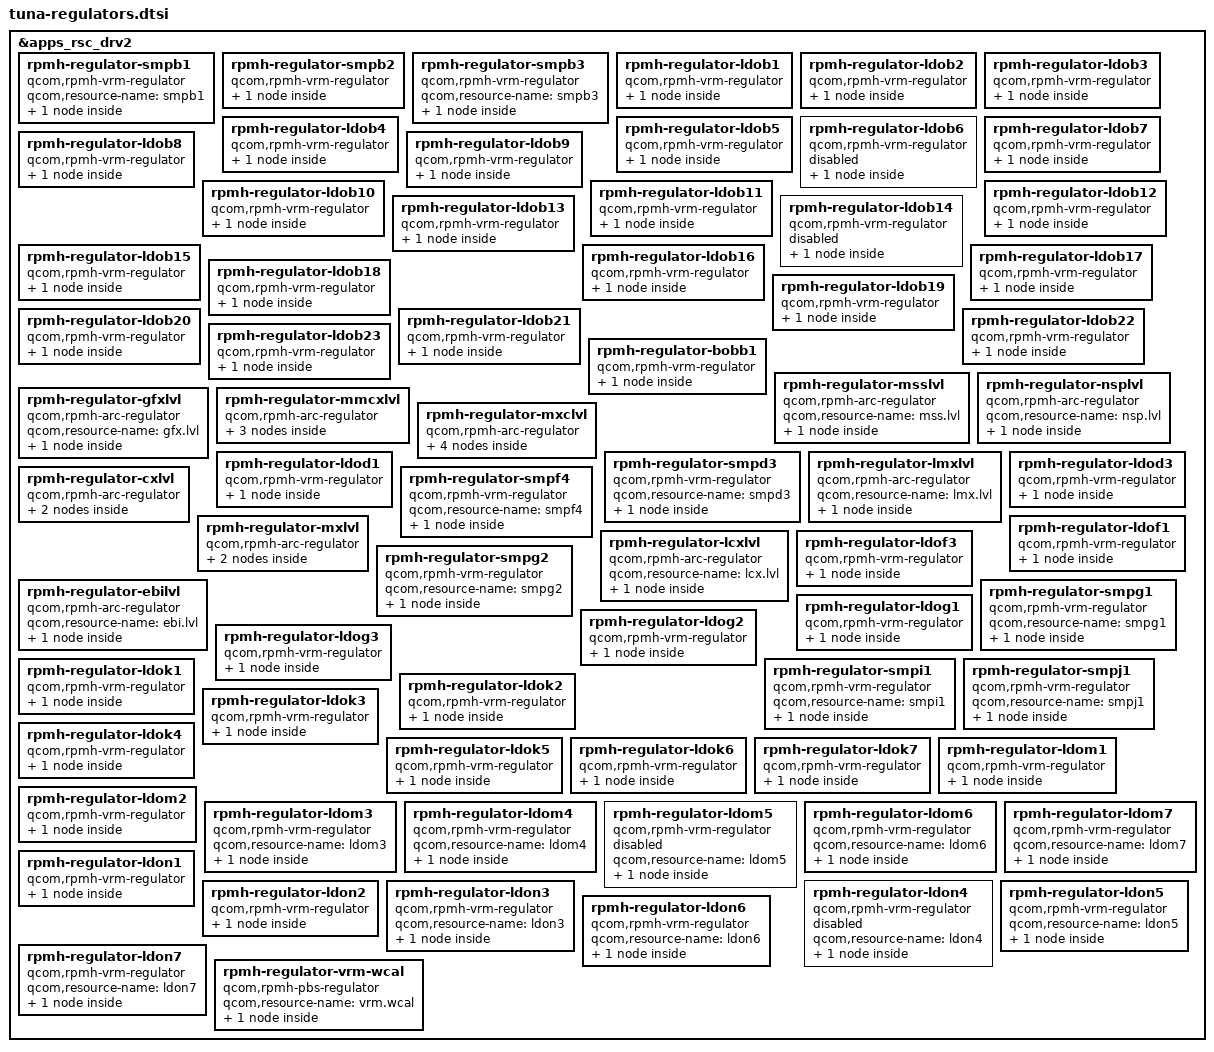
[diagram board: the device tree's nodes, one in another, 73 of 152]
// SPDX-License-Identifier: BSD-3-Clause
/*
 * Copyright (c) Qualcomm Technologies, Inc. and/or its subsidiaries.
 */

#include <dt-bindings/regulator/qcom,rpmh-regulator-levels.h>

&apps_rsc_drv2 {
	rpmh-regulator-smpb1 {
		compatible = "qcom,rpmh-vrm-regulator";
		qcom,resource-name = "smpb1";

		S1B: pmxr2230_s1: vreg-pmxr2230-s1 {
			regulator-name = "pmxr2230_s1";
			qcom,set = <RPMH_REGULATOR_SET_ALL>;
			regulator-min-microvolt = <1840000>;
			regulator-max-microvolt = <2104000>;
			qcom,init-voltage = <1840000>;
		};
	};

	rpmh-regulator-smpb2 {
		compatible = "qcom,rpmh-vrm-regulator";
		qcom,resource-name = "smpb2";
		qcom,regulator-type = "pmic5-ftsmps";
		qcom,supported-modes = <RPMH_REGULATOR_MODE_RET
					RPMH_REGULATOR_MODE_HPM>;
		qcom,mode-threshold-currents = <0 50000>;

		S2B: pmxr2230_s2: vreg-pmxr2230-s2 {
			regulator-name = "pmxr2230_s2";
			qcom,set = <RPMH_REGULATOR_SET_ALL>;
			regulator-min-microvolt = <1240000>;
			regulator-max-microvolt = <1408000>;
			qcom,init-voltage = <1240000>;
			qcom,init-mode = <RPMH_REGULATOR_MODE_RET>;
		};
	};

	rpmh-regulator-smpb3 {
		compatible = "qcom,rpmh-vrm-regulator";
		qcom,resource-name = "smpb3";

		S3B: pmxr2230_s3: vreg-pmxr2230-s3 {
			regulator-name = "pmxr2230_s3";
			qcom,set = <RPMH_REGULATOR_SET_ALL>;
			regulator-min-microvolt = <750000>;
			regulator-max-microvolt = <1040000>;
			qcom,init-voltage = <952000>;
		};
	};

	rpmh-regulator-ldob1 {
		compatible = "qcom,rpmh-vrm-regulator";
		qcom,resource-name = "ldob1";
		qcom,regulator-type = "pmic5-ldo";
		qcom,supported-modes =
			<RPMH_REGULATOR_MODE_LPM
			 RPMH_REGULATOR_MODE_HPM>;
		qcom,mode-threshold-currents = <0 30000>;

		L1B: pmxr2230_l1: vreg-pmxr2230-l1 {
			regulator-name = "pmxr2230_l1";
			qcom,set = <RPMH_REGULATOR_SET_ALL>;
			regulator-min-microvolt = <866000>;
			regulator-max-microvolt = <958000>;
			qcom,init-voltage = <912000>;
			qcom,init-mode = <RPMH_REGULATOR_MODE_HPM>;
		};
	};

	rpmh-regulator-ldob2 {
		compatible = "qcom,rpmh-vrm-regulator";
		qcom,resource-name = "ldob2";
		qcom,regulator-type = "pmic5-ldo";
		qcom,supported-modes =
			<RPMH_REGULATOR_MODE_LPM
			 RPMH_REGULATOR_MODE_HPM>;
		qcom,mode-threshold-currents = <0 30000>;
		proxy-supply = <&L2B>;

		L2B: pmxr2230_l2: vreg-pmxr2230-l2 {
			regulator-name = "pmxr2230_l2";
			qcom,set = <RPMH_REGULATOR_SET_ALL>;
			regulator-min-microvolt = <880000>;
			regulator-max-microvolt = <925000>;
			qcom,init-voltage = <880000>;
			qcom,init-mode = <RPMH_REGULATOR_MODE_HPM>;
			qcom,proxy-consumer-enable;
			qcom,proxy-consumer-current = <98000>;
		};
	};

	rpmh-regulator-ldob3 {
		compatible = "qcom,rpmh-vrm-regulator";
		qcom,resource-name = "ldob3";
		qcom,regulator-type = "pmic5-ldo";
		qcom,supported-modes =
			<RPMH_REGULATOR_MODE_LPM
			 RPMH_REGULATOR_MODE_HPM>;
		qcom,mode-threshold-currents = <0 30000>;

		L3B: pmxr2230_l3: vreg-pmxr2230-l3 {
			regulator-name = "pmxr2230_l3";
			qcom,set = <RPMH_REGULATOR_SET_ALL>;
			regulator-min-microvolt = <720000>;
			regulator-max-microvolt = <950000>;
			qcom,init-voltage = <880000>;
			qcom,init-mode = <RPMH_REGULATOR_MODE_HPM>;
		};
	};

	rpmh-regulator-ldob4 {
		compatible = "qcom,rpmh-vrm-regulator";
		qcom,resource-name = "ldob4";
		qcom,regulator-type = "pmic5-ldo";
		qcom,supported-modes =
			<RPMH_REGULATOR_MODE_LPM
			 RPMH_REGULATOR_MODE_HPM>;
		qcom,mode-threshold-currents = <0 30000>;
		proxy-supply = <&L4B>;

		L4B: pmxr2230_l4: vreg-pmxr2230-l4 {
			regulator-name = "pmxr2230_l4";
			qcom,set = <RPMH_REGULATOR_SET_ALL>;
			regulator-min-microvolt = <1200000>;
			regulator-max-microvolt = <1200000>;
			qcom,init-voltage = <1200000>;
			qcom,init-mode = <RPMH_REGULATOR_MODE_HPM>;
			qcom,proxy-consumer-enable;
			qcom,proxy-consumer-current = <16600>;
		};
	};

	rpmh-regulator-ldob5 {
		compatible = "qcom,rpmh-vrm-regulator";
		qcom,resource-name = "ldob5";
		qcom,regulator-type = "pmic5-ldo";
		qcom,supported-modes =
			<RPMH_REGULATOR_MODE_RET
			 RPMH_REGULATOR_MODE_LPM
			 RPMH_REGULATOR_MODE_HPM>;
		qcom,mode-threshold-currents = <0 10000 30000>;

		L5B: pmxr2230_l5: vreg-pmxr2230-l5 {
			regulator-name = "pmxr2230_l5";
			qcom,set = <RPMH_REGULATOR_SET_ALL>;
			regulator-min-microvolt = <1200000>;
			regulator-max-microvolt = <1200000>;
			qcom,init-voltage = <1200000>;
			qcom,init-mode = <RPMH_REGULATOR_MODE_LPM>;
		};
	};

	rpmh-regulator-ldob6 {
		compatible = "qcom,rpmh-vrm-regulator";
		qcom,resource-name = "ldob6";
		qcom,regulator-type = "pmic5-ldo";
		qcom,supported-modes =
			<RPMH_REGULATOR_MODE_LPM
			 RPMH_REGULATOR_MODE_HPM>;
		qcom,mode-threshold-currents = <0 30000>;
		status = "disabled";

		L6B: pmxr2230_l6: vreg-pmxr2230-l6 {
			regulator-name = "pmxr2230_l6";
			qcom,set = <RPMH_REGULATOR_SET_ALL>;
			regulator-min-microvolt = <1170000>;
			regulator-max-microvolt = <1370000>;
			qcom,init-voltage = <1256000>;
			qcom,init-mode = <RPMH_REGULATOR_MODE_HPM>;
			status = "disabled";
		};
	};

	rpmh-regulator-ldob7 {
		compatible = "qcom,rpmh-vrm-regulator";
		qcom,resource-name = "ldob7";
		qcom,regulator-type = "pmic5-ldo";
		qcom,supported-modes =
			<RPMH_REGULATOR_MODE_LPM
			 RPMH_REGULATOR_MODE_HPM>;
		qcom,mode-threshold-currents = <0 30000>;

		L7B: pmxr2230_l7: vreg-pmxr2230-l7 {
			regulator-name = "pmxr2230_l7";
			qcom,set = <RPMH_REGULATOR_SET_ALL>;
			regulator-min-microvolt = <1800000>;
			regulator-max-microvolt = <1800000>;
			qcom,init-voltage = <1800000>;
			qcom,init-mode = <RPMH_REGULATOR_MODE_HPM>;
		};
	};

	rpmh-regulator-ldob8 {
		compatible = "qcom,rpmh-vrm-regulator";
		qcom,resource-name = "ldob8";
		qcom,regulator-type = "pmic5-ldo";
		qcom,supported-modes =
			<RPMH_REGULATOR_MODE_LPM
			 RPMH_REGULATOR_MODE_HPM>;
		qcom,mode-threshold-currents = <0 30000>;
		proxy-supply = <&L8B>;

		L8B: pmxr2230_l8: vreg-pmxr2230-l8 {
			regulator-name = "pmxr2230_l8";
			qcom,set = <RPMH_REGULATOR_SET_ALL>;
			regulator-min-microvolt = <1800000>;
			regulator-max-microvolt = <1800000>;
			qcom,init-voltage = <1800000>;
			qcom,init-mode = <RPMH_REGULATOR_MODE_HPM>;
			qcom,proxy-consumer-enable;
			qcom,proxy-consumer-current = <154000>;
		};
	};

	rpmh-regulator-ldob9 {
		compatible = "qcom,rpmh-vrm-regulator";
		qcom,resource-name = "ldob9";
		qcom,regulator-type = "pmic5-ldo";
		qcom,supported-modes =
			<RPMH_REGULATOR_MODE_LPM
			 RPMH_REGULATOR_MODE_HPM>;
		qcom,mode-threshold-currents = <0 30000>;

		L9B: pmxr2230_l9: vreg-pmxr2230-l9 {
			regulator-name = "pmxr2230_l9";
			qcom,set = <RPMH_REGULATOR_SET_ALL>;
			regulator-min-microvolt = <756000>;
			regulator-max-microvolt = <816000>;
			qcom,init-voltage = <800000>;
			qcom,init-mode = <RPMH_REGULATOR_MODE_HPM>;
		};
	};

	rpmh-regulator-ldob10 {
		compatible = "qcom,rpmh-vrm-regulator";
		qcom,resource-name = "ldob10";
		qcom,regulator-type = "pmic5-ldo";
		qcom,supported-modes =
			<RPMH_REGULATOR_MODE_LPM
			 RPMH_REGULATOR_MODE_HPM>;
		qcom,mode-threshold-currents = <0 30000>;

		L10B: pmxr2230_l10: vreg-pmxr2230-l10 {
			regulator-name = "pmxr2230_l10";
			qcom,set = <RPMH_REGULATOR_SET_ALL>;
			regulator-min-microvolt = <866000>;
			regulator-max-microvolt = <931000>;
			qcom,init-voltage = <912000>;
			qcom,init-mode = <RPMH_REGULATOR_MODE_HPM>;
		};
	};

	rpmh-regulator-ldob11 {
		compatible = "qcom,rpmh-vrm-regulator";
		qcom,resource-name = "ldob11";
		qcom,regulator-type = "pmic5-ldo";
		qcom,supported-modes =
			<RPMH_REGULATOR_MODE_LPM
			 RPMH_REGULATOR_MODE_HPM>;
		qcom,mode-threshold-currents = <0 30000>;

		L11B: pmxr2230_l11: vreg-pmxr2230-l11 {
			regulator-name = "pmxr2230_l11";
			qcom,set = <RPMH_REGULATOR_SET_ALL>;
			regulator-min-microvolt = <1080000>;
			regulator-max-microvolt = <2000000>;
			qcom,init-voltage = <1800000>;
			qcom,init-mode = <RPMH_REGULATOR_MODE_HPM>;
		};
	};

	rpmh-regulator-ldob12 {
		compatible = "qcom,rpmh-vrm-regulator";
		qcom,resource-name = "ldob12";
		qcom,regulator-type = "pmic5-ldo";
		qcom,supported-modes =
			<RPMH_REGULATOR_MODE_LPM
			 RPMH_REGULATOR_MODE_HPM>;
		qcom,mode-threshold-currents = <0 10000>;

		L12B: pmxr2230_l12: vreg-pmxr2230-l12 {
			regulator-name = "pmxr2230_l12";
			qcom,set = <RPMH_REGULATOR_SET_ALL>;
			regulator-min-microvolt = <2400000>;
			regulator-max-microvolt = <3300000>;
			qcom,init-voltage = <2504000>;
			qcom,init-mode = <RPMH_REGULATOR_MODE_HPM>;
		};
	};

	rpmh-regulator-ldob13 {
		compatible = "qcom,rpmh-vrm-regulator";
		qcom,resource-name = "ldob13";
		qcom,regulator-type = "pmic5-ldo";
		qcom,supported-modes =
			<RPMH_REGULATOR_MODE_LPM
			 RPMH_REGULATOR_MODE_HPM>;
		qcom,mode-threshold-currents = <0 10000>;

		L13B: pmxr2230_l13: vreg-pmxr2230-l13 {
			regulator-name = "pmxr2230_l13";
			qcom,set = <RPMH_REGULATOR_SET_ALL>;
			regulator-min-microvolt = <2700000>;
			regulator-max-microvolt = <3300000>;
			qcom,init-voltage = <2960000>;
			qcom,init-mode = <RPMH_REGULATOR_MODE_HPM>;
		};
	};

	rpmh-regulator-ldob14 {
		compatible = "qcom,rpmh-vrm-regulator";
		qcom,resource-name = "ldob14";
		qcom,regulator-type = "pmic5-ldo";
		qcom,supported-modes =
			<RPMH_REGULATOR_MODE_LPM
			 RPMH_REGULATOR_MODE_HPM>;
		qcom,mode-threshold-currents = <0 10000>;
		status = "disabled";

		L14B: pmxr2230_l14: vreg-pmxr2230-l14 {
			regulator-name = "pmxr2230_l14";
			qcom,set = <RPMH_REGULATOR_SET_ALL>;
			regulator-min-microvolt = <1504000>;
			regulator-max-microvolt = <3544000>;
			qcom,init-voltage = <2800000>;
			qcom,init-mode = <RPMH_REGULATOR_MODE_HPM>;
			status = "disabled";
		};
	};

	rpmh-regulator-ldob15 {
		compatible = "qcom,rpmh-vrm-regulator";
		qcom,resource-name = "ldob15";
		qcom,regulator-type = "pmic5-ldo";
		qcom,supported-modes =
			<RPMH_REGULATOR_MODE_LPM
			 RPMH_REGULATOR_MODE_HPM>;
		qcom,mode-threshold-currents = <0 10000>;

		L15B: pmxr2230_l15: vreg-pmxr2230-l15 {
			regulator-name = "pmxr2230_l15";
			qcom,set = <RPMH_REGULATOR_SET_ALL>;
			regulator-min-microvolt = <1620000>;
			regulator-max-microvolt = <3300000>;
			qcom,init-voltage = <1800000>;
			qcom,init-mode = <RPMH_REGULATOR_MODE_HPM>;
		};
	};

	rpmh-regulator-ldob16 {
		compatible = "qcom,rpmh-vrm-regulator";
		qcom,resource-name = "ldob16";
		qcom,regulator-type = "pmic5-ldo";
		qcom,supported-modes =
			<RPMH_REGULATOR_MODE_LPM
			 RPMH_REGULATOR_MODE_HPM>;
		qcom,mode-threshold-currents = <0 10000>;

		L16B: pmxr2230_l16: vreg-pmxr2230-l16 {
			regulator-name = "pmxr2230_l16";
			qcom,set = <RPMH_REGULATOR_SET_ALL>;
			regulator-min-microvolt = <2600000>;
			regulator-max-microvolt = <3544000>;
			qcom,init-voltage = <3008000>;
			qcom,init-mode = <RPMH_REGULATOR_MODE_HPM>;
		};
	};

	rpmh-regulator-ldob17 {
		compatible = "qcom,rpmh-vrm-regulator";
		qcom,resource-name = "ldob17";
		qcom,regulator-type = "pmic5-ldo";
		qcom,supported-modes =
			<RPMH_REGULATOR_MODE_LPM
			 RPMH_REGULATOR_MODE_HPM>;
		qcom,mode-threshold-currents = <0 10000>;

		L17B: pmxr2230_l17: vreg-pmxr2230-l17 {
			regulator-name = "pmxr2230_l17";
			qcom,set = <RPMH_REGULATOR_SET_ALL>;
			regulator-min-microvolt = <2700000>;
			regulator-max-microvolt = <3544000>;
			qcom,init-voltage = <3104000>;
			qcom,init-mode = <RPMH_REGULATOR_MODE_HPM>;
		};
	};

	rpmh-regulator-ldob18 {
		compatible = "qcom,rpmh-vrm-regulator";
		qcom,resource-name = "ldob18";
		qcom,regulator-type = "pmic5-ldo";
		qcom,supported-modes =
			<RPMH_REGULATOR_MODE_LPM
			 RPMH_REGULATOR_MODE_HPM>;
		qcom,mode-threshold-currents = <0 10000>;

		L18B: pmxr2230_l18: vreg-pmxr2230-l18 {
			regulator-name = "pmxr2230_l18";
			qcom,set = <RPMH_REGULATOR_SET_ALL>;
			regulator-min-microvolt = <1600000>;
			regulator-max-microvolt = <3544000>;
			qcom,init-voltage = <2800000>;
			qcom,init-mode = <RPMH_REGULATOR_MODE_HPM>;
		};
	};

	rpmh-regulator-ldob19 {
		compatible = "qcom,rpmh-vrm-regulator";
		qcom,resource-name = "ldob19";
		qcom,regulator-type = "pmic5-ldo";
		qcom,supported-modes =
			<RPMH_REGULATOR_MODE_LPM
			 RPMH_REGULATOR_MODE_HPM>;
		qcom,mode-threshold-currents = <0 10000>;
		proxy-supply = <&L19B>;

		L19B: pmxr2230_l19: vreg-pmxr2230-l19 {
			regulator-name = "pmxr2230_l19";
			qcom,set = <RPMH_REGULATOR_SET_ALL>;
			regulator-min-microvolt = <2650000>;
			regulator-max-microvolt = <3544000>;
			qcom,init-voltage = <3000000>;
			qcom,init-mode = <RPMH_REGULATOR_MODE_HPM>;
			qcom,proxy-consumer-enable;
			qcom,proxy-consumer-current = <10000>;
		};
	};

	rpmh-regulator-ldob20 {
		compatible = "qcom,rpmh-vrm-regulator";
		qcom,resource-name = "ldob20";
		qcom,regulator-type = "pmic5-ldo";
		qcom,supported-modes =
			<RPMH_REGULATOR_MODE_LPM
			 RPMH_REGULATOR_MODE_HPM>;
		qcom,mode-threshold-currents = <0 10000>;

		L20B: pmxr2230_l20: vreg-pmxr2230-l20 {
			regulator-name = "pmxr2230_l20";
			qcom,set = <RPMH_REGULATOR_SET_ALL>;
			regulator-min-microvolt = <1504000>;
			regulator-max-microvolt = <3544000>;
			qcom,init-voltage = <1800000>;
			qcom,init-mode = <RPMH_REGULATOR_MODE_HPM>;
		};
	};

	rpmh-regulator-ldob21 {
		compatible = "qcom,rpmh-vrm-regulator";
		qcom,resource-name = "ldob21";
		qcom,regulator-type = "pmic5-ldo";
		qcom,supported-modes =
			<RPMH_REGULATOR_MODE_LPM
			 RPMH_REGULATOR_MODE_HPM>;
		qcom,mode-threshold-currents = <0 10000>;

		L21B: pmxr2230_l21: vreg-pmxr2230-l21 {
			regulator-name = "pmxr2230_l21";
			qcom,set = <RPMH_REGULATOR_SET_ALL>;
			regulator-min-microvolt = <1504000>;
			regulator-max-microvolt = <3544000>;
			qcom,init-voltage = <1800000>;
			qcom,init-mode = <RPMH_REGULATOR_MODE_HPM>;
		};
	};

	rpmh-regulator-ldob22 {
		compatible = "qcom,rpmh-vrm-regulator";
		qcom,resource-name = "ldob22";
		qcom,regulator-type = "pmic5-ldo";
		qcom,supported-modes =
			<RPMH_REGULATOR_MODE_LPM
			 RPMH_REGULATOR_MODE_HPM>;
		qcom,mode-threshold-currents = <0 10000>;

		L22B: pmxr2230_l22: vreg-pmxr2230-l22 {
			regulator-name = "pmxr2230_l22";
			qcom,set = <RPMH_REGULATOR_SET_ALL>;
			regulator-min-microvolt = <2700000>;
			regulator-max-microvolt = <3544000>;
			qcom,init-voltage = <3200000>;
			qcom,init-mode = <RPMH_REGULATOR_MODE_HPM>;
		};
	};

	rpmh-regulator-ldob23 {
		compatible = "qcom,rpmh-vrm-regulator";
		qcom,resource-name = "ldob23";
		qcom,regulator-type = "pmic5-ldo";
		qcom,supported-modes =
			<RPMH_REGULATOR_MODE_LPM
			 RPMH_REGULATOR_MODE_HPM>;
		qcom,mode-threshold-currents = <0 10000>;

		L23B: pmxr2230_l23: vreg-pmxr2230-l23 {
			regulator-name = "pmxr2230_l23";
			qcom,set = <RPMH_REGULATOR_SET_ALL>;
			regulator-min-microvolt = <1650000>;
			regulator-max-microvolt = <3544000>;
			qcom,init-voltage = <1800000>;
			qcom,init-mode = <RPMH_REGULATOR_MODE_HPM>;
		};
	};

	rpmh-regulator-bobb1 {
		compatible = "qcom,rpmh-vrm-regulator";
		qcom,resource-name = "bobb1";
		qcom,regulator-type = "pmic5-bob";
		qcom,supported-modes =
			<RPMH_REGULATOR_MODE_PASS
			 RPMH_REGULATOR_MODE_LPM
			 RPMH_REGULATOR_MODE_HPM>;
		qcom,mode-threshold-currents = <0 1000000 2000000>;

		BOB: pmxr2230_bob: vreg-pmxr2230-bob1 {
			regulator-name = "pmxr2230_bob";
			qcom,set = <RPMH_REGULATOR_SET_ALL>;
			regulator-min-microvolt = <3008000>;
			regulator-max-microvolt = <3960000>;
			qcom,init-voltage = <3296000>;
		};
	};

	rpmh-regulator-msslvl {
		compatible = "qcom,rpmh-arc-regulator";
		qcom,resource-name = "mss.lvl";

		VDD_MODEM_LEVEL:
		S1D_LEVEL:
		pm_v6d_s1_level: vreg-pm_v6d-s1-level {
			regulator-name = "pm_v6d_s1_level";
			qcom,set = <RPMH_REGULATOR_SET_ALL>;
			regulator-min-microvolt =
				<RPMH_REGULATOR_LEVEL_RETENTION>;
			regulator-max-microvolt = <RPMH_REGULATOR_LEVEL_MAX>;
			qcom,init-voltage-level =
				<RPMH_REGULATOR_LEVEL_RETENTION>;
		};
	};

	rpmh-regulator-nsplvl {
		compatible = "qcom,rpmh-arc-regulator";
		qcom,resource-name = "nsp.lvl";

		VDD_NSP1_LEVEL:
		S4D_LEVEL:
		pm_v6d_s4_level: vreg-pm_v6d-s4-level {
			regulator-name = "pm-v6d_s4_level";
			qcom,set = <RPMH_REGULATOR_SET_ALL>;
			regulator-min-microvolt =
				<RPMH_REGULATOR_LEVEL_RETENTION>;
			regulator-max-microvolt = <RPMH_REGULATOR_LEVEL_MAX>;
			qcom,init-voltage-level =
				<RPMH_REGULATOR_LEVEL_RETENTION>;
		};
	};

	rpmh-regulator-gfxlvl {
		compatible = "qcom,rpmh-arc-regulator";
		qcom,resource-name = "gfx.lvl";

		VDD_GFX_LEVEL:
		S5F_LEVEL:
		pm_v8f_s5_level: vreg-pm_v8f-s5-level {
			regulator-name = "pm_v8f_s5_level";
			qcom,set = <RPMH_REGULATOR_SET_ALL>;
			regulator-min-microvolt =
				<RPMH_REGULATOR_LEVEL_RETENTION>;
			regulator-max-microvolt = <RPMH_REGULATOR_LEVEL_MAX>;
			qcom,init-voltage-level =
				<RPMH_REGULATOR_LEVEL_RETENTION>;
		};
	};

	rpmh-regulator-mmcxlvl {
		compatible = "qcom,rpmh-arc-regulator";
		qcom,resource-name = "mmcx.lvl";
		proxy-supply = <&VDD_MMCX_LEVEL>;

		VDD_MMCX_LEVEL: VDD_MM_LEVEL: S2F_LEVEL:
		pm_v8f_s2_level: vreg-pm-v8f-s2-level {
			regulator-name = "pm_v8f_s2_level";
			qcom,set = <RPMH_REGULATOR_SET_ALL>;
			regulator-min-microvolt =
				<RPMH_REGULATOR_LEVEL_LOW_SVS_D1>;
			regulator-max-microvolt =
				<RPMH_REGULATOR_LEVEL_MAX>;
			qcom,init-voltage-level =
				<RPMH_REGULATOR_LEVEL_TURBO>;
			qcom,proxy-consumer-enable;
			qcom,proxy-consumer-voltage =
				<RPMH_REGULATOR_LEVEL_TURBO
				 RPMH_REGULATOR_LEVEL_MAX>;
		};

		VDD_MMCX_LEVEL_AO: VDD_MM_LEVEL_AO: S2F_LEVEL_AO:
		pm_v8f_s2_level_ao: vreg-pm-v8f-s2-level-ao {
			regulator-name = "pm_v8f_s2_level_ao";
			qcom,set = <RPMH_REGULATOR_SET_ACTIVE>;
			regulator-min-microvolt =
				<RPMH_REGULATOR_LEVEL_LOW_SVS_D1>;
			regulator-max-microvolt =
				<RPMH_REGULATOR_LEVEL_MAX>;
			qcom,init-voltage-level =
				<RPMH_REGULATOR_LEVEL_LOW_SVS_D1>;
		};

		vreg-pm-v8f-s2-level-so {
			regulator-name = "pm_v8i_s2_level_so";
			qcom,set = <RPMH_REGULATOR_SET_SLEEP>;
			regulator-min-microvolt =
				<RPMH_REGULATOR_LEVEL_LOW_SVS_D1>;
			regulator-max-microvolt =
				<RPMH_REGULATOR_LEVEL_MAX>;
			qcom,init-voltage-level =
				<RPMH_REGULATOR_LEVEL_LOW_SVS_D1>;
		};
	};

	rpmh-regulator-mxclvl {
		compatible = "qcom,rpmh-arc-regulator";
		qcom,resource-name = "mxc.lvl";
		proxy-supply = <&VDD_MXC_LEVEL>;

		VDD_MXC_LEVEL:
		S2D_LEVEL:
		pm_v6d_s2_level: vreg-pm_v6d-s2-level {
			regulator-name = "pm_v6d_s2_level";
			qcom,set = <RPMH_REGULATOR_SET_ALL>;
			regulator-min-microvolt =
				<RPMH_REGULATOR_LEVEL_RETENTION>;
			regulator-max-microvolt = <RPMH_REGULATOR_LEVEL_MAX>;
			qcom,init-voltage-level =
				<RPMH_REGULATOR_LEVEL_TURBO>;
			qcom,proxy-consumer-enable;
			qcom,proxy-consumer-voltage =
				<RPMH_REGULATOR_LEVEL_TURBO
					RPMH_REGULATOR_LEVEL_MAX>;
		};

		VDD_MXC_LEVEL_AO:
		S2D_LEVEL_AO:
		pm_v6d_s2_level_ao: vreg-pm_v6d-s2-level-ao {
			regulator-name = "pm_v6d_s2_level_ao";
			qcom,set = <RPMH_REGULATOR_SET_ACTIVE>;
			regulator-min-microvolt =
				<RPMH_REGULATOR_LEVEL_RETENTION>;
			regulator-max-microvolt = <RPMH_REGULATOR_LEVEL_MAX>;
			qcom,init-voltage-level =
				<RPMH_REGULATOR_LEVEL_RETENTION>;
		};

		VDD_MXC_MMCX_VOTER_LEVEL: VDD_MXC_MM_VOTER_LEVEL:
		VDD_MM_MXC_VOTER_LEVEL: vreg-pm_v6d-s2-mmcx-voter-level {
			regulator-name = "pm_v6d_s2_mmcx_voter_level";
			pm_v6d_s2_mmcx_voter_level-parent-supply =
				<&VDD_MMCX_LEVEL>;
			qcom,set = <RPMH_REGULATOR_SET_ALL>;
			regulator-min-microvolt =
				<RPMH_REGULATOR_LEVEL_MIN_SVS>;
			regulator-max-microvolt =
				<RPMH_REGULATOR_LEVEL_MAX>;
			qcom,init-voltage-level =
				<RPMH_REGULATOR_LEVEL_MIN_SVS>;
		};

		VDD_MXC_GFX_VOTER_LEVEL: VDD_GFX_MXC_VOTER_LEVEL:
			vreg-pm_v6d-s2-gfx-voter-level {
			regulator-name = "pm_v6d_s2_gfx_voter_level";
			pm_v6d_s2_gfx_voter_level-parent-supply = <&VDD_GFX_LEVEL>;
			qcom,set = <RPMH_REGULATOR_SET_ALL>;
			regulator-min-microvolt =
				<RPMH_REGULATOR_LEVEL_MIN_SVS>;
			regulator-max-microvolt =
				<RPMH_REGULATOR_LEVEL_MAX>;
			qcom,init-voltage-level =
				<RPMH_REGULATOR_LEVEL_MIN_SVS>;
		};
	};

	rpmh-regulator-smpd3 {
		compatible = "qcom,rpmh-vrm-regulator";
		qcom,resource-name = "smpd3";

		S3D: pm_v6d_s3: vreg-pm_v6d-s3 {
			regulator-name = "pm_v6d_s3";
			qcom,set = <RPMH_REGULATOR_SET_ALL>;
			regulator-min-microvolt = <870000>;
			regulator-max-microvolt = <970000>;
			qcom,init-voltage = <904000>;
		};
	};

	rpmh-regulator-ldod1 {
		compatible = "qcom,rpmh-vrm-regulator";
		qcom,resource-name = "ldod1";
		qcom,regulator-type = "pmic5-ldo";
		qcom,supported-modes =
			<RPMH_REGULATOR_MODE_LPM
			 RPMH_REGULATOR_MODE_HPM>;
		qcom,mode-threshold-currents = <0 30000>;

		L1D: pm_v6d_l1: vreg-pm_v6d-l1 {
			regulator-name = "pm_v6d_l1";
			qcom,set = <RPMH_REGULATOR_SET_ALL>;
			regulator-min-microvolt = <1710000>;
			regulator-max-microvolt = <1950000>;
			qcom,init-voltage = <1800000>;
			qcom,init-mode = <RPMH_REGULATOR_MODE_HPM>;
		};
	};

	rpmh-regulator-lmxlvl {
		compatible = "qcom,rpmh-arc-regulator";
		qcom,resource-name = "lmx.lvl";

		VDD_LPI_MX_LEVEL:
		L2D_LEVEL:
		pm_v6d_l2_level: vreg-pm_v6d-l2-level {
			regulator-name = "pm_v6d_l2_level";
			qcom,set = <RPMH_REGULATOR_SET_ALL>;
			regulator-min-microvolt =
				<RPMH_REGULATOR_LEVEL_RETENTION>;
			regulator-max-microvolt = <RPMH_REGULATOR_LEVEL_MAX>;
			qcom,init-voltage-level =
				<RPMH_REGULATOR_LEVEL_RETENTION>;
		};
	};

	rpmh-regulator-ldod3 {
		compatible = "qcom,rpmh-vrm-regulator";
		qcom,resource-name = "ldod3";
		qcom,regulator-type = "pmic5-ldo";
		qcom,supported-modes =
			<RPMH_REGULATOR_MODE_LPM
			 RPMH_REGULATOR_MODE_HPM>;
		qcom,mode-threshold-currents = <0 30000>;
		proxy-supply = <&L3D>;

		L3D: pm_v6d_l3: vreg-pm_v6d-l3 {
			regulator-name = "pm_v6d_l3";
			qcom,set = <RPMH_REGULATOR_SET_ALL>;
			regulator-min-microvolt = <1030000>;
			regulator-max-microvolt = <1100000>;
			qcom,init-voltage = <1060000>;
			qcom,init-mode = <RPMH_REGULATOR_MODE_HPM>;
			qcom,proxy-consumer-enable;
			qcom,proxy-consumer-current = <220000>;
		};
	};

	rpmh-regulator-cxlvl {
		compatible = "qcom,rpmh-arc-regulator";
		qcom,resource-name = "cx.lvl";
		proxy-supply = <&VDD_CX_LEVEL>;

		VDD_CX_LEVEL:
		S1F_LEVEL:
		pm_v8f_s1_level: vreg-pm_v8f-s1-level {
			regulator-name = "pm_v8f_s1_level";
			qcom,set = <RPMH_REGULATOR_SET_ALL>;
			regulator-min-microvolt =
				<RPMH_REGULATOR_LEVEL_RETENTION>;
			regulator-max-microvolt = <RPMH_REGULATOR_LEVEL_MAX>;
			qcom,init-voltage-level =
				<RPMH_REGULATOR_LEVEL_TURBO>;
			qcom,proxy-consumer-enable;
			qcom,proxy-consumer-voltage =
				<RPMH_REGULATOR_LEVEL_TURBO
				RPMH_REGULATOR_LEVEL_MAX>;
		};

		VDD_CX_LEVEL_AO:
		S1F_LEVEL_AO:
		pm_v8f_s1_level_ao: vreg-pm_v8f-s1-level-ao {
			regulator-name = "pm_v8f_s1_level_ao";
			qcom,set = <RPMH_REGULATOR_SET_ACTIVE>;
			regulator-min-microvolt =
				<RPMH_REGULATOR_LEVEL_RETENTION>;
			regulator-max-microvolt = <RPMH_REGULATOR_LEVEL_MAX>;
			qcom,init-voltage-level =
				<RPMH_REGULATOR_LEVEL_RETENTION>;
		};
	};

	rpmh-regulator-smpf4 {
		compatible = "qcom,rpmh-vrm-regulator";
		qcom,resource-name = "smpf4";

		S4F: pm_v8f_s4: vreg-pm_v8f-s4 {
			regulator-name = "pm_v8f_s4";
			qcom,set = <RPMH_REGULATOR_SET_ALL>;
			regulator-min-microvolt = <300000>;
			regulator-max-microvolt = <570000>;
			qcom,init-voltage = <500000>;
		};
	};

	rpmh-regulator-mxlvl {
		compatible = "qcom,rpmh-arc-regulator";
		qcom,resource-name = "mx.lvl";
		proxy-supply = <&VDD_MXA_LEVEL>;

		VDD_MX_LEVEL:
		VDD_MXA_LEVEL:
		S8F_LEVEL:
		pm_v8f_s8_level: vreg-pm_v8f-s8-level {
			regulator-name = "pm_v8f_s8_level";
			qcom,set = <RPMH_REGULATOR_SET_ALL>;
			regulator-min-microvolt =
				<RPMH_REGULATOR_LEVEL_RETENTION>;
			regulator-max-microvolt = <RPMH_REGULATOR_LEVEL_MAX>;
			qcom,init-voltage-level =
				<RPMH_REGULATOR_LEVEL_TURBO>;
			qcom,proxy-consumer-enable;
			qcom,proxy-consumer-voltage =
				<RPMH_REGULATOR_LEVEL_TURBO
				RPMH_REGULATOR_LEVEL_MAX>;
		};

		VDD_MXA_LEVEL_AO:
		S8F_LEVEL_AO:
		pm_v8f_s8_level_ao: vreg-pm_v8f-s8-level-ao {
			regulator-name = "pm_v8f_s8_level_ao";
			qcom,set = <RPMH_REGULATOR_SET_ACTIVE>;
			regulator-min-microvolt =
				<RPMH_REGULATOR_LEVEL_RETENTION>;
			regulator-max-microvolt = <RPMH_REGULATOR_LEVEL_MAX>;
			qcom,init-voltage-level =
				<RPMH_REGULATOR_LEVEL_RETENTION>;
		};
	};

	rpmh-regulator-ldof1 {
		compatible = "qcom,rpmh-vrm-regulator";
		qcom,resource-name = "ldof1";
		qcom,regulator-type = "pmic5-ldo";
		qcom,supported-modes =
			<RPMH_REGULATOR_MODE_LPM
			 RPMH_REGULATOR_MODE_HPM>;
		qcom,mode-threshold-currents = <0 30000>;

		L1F: pm_v8f_l1: vreg-pm_v8f-l1 {
			regulator-name = "pm_v8f_l1";
			qcom,set = <RPMH_REGULATOR_SET_ALL>;
			regulator-min-microvolt = <866000>;
			regulator-max-microvolt = <958000>;
			qcom,init-voltage = <912000>;
			qcom,init-mode = <RPMH_REGULATOR_MODE_HPM>;
		};
	};

	rpmh-regulator-lcxlvl {
		compatible = "qcom,rpmh-arc-regulator";
		qcom,resource-name = "lcx.lvl";

		VDD_LPI_CX_LEVEL:
		L2F_LEVEL:
		pm_v8f_l2_level: vreg-pm_v8-l2-level {
			regulator-name = "pm_v8f_l2_level";
			qcom,set = <RPMH_REGULATOR_SET_ALL>;
			regulator-min-microvolt =
				<RPMH_REGULATOR_LEVEL_RETENTION>;
			regulator-max-microvolt = <RPMH_REGULATOR_LEVEL_MAX>;
			qcom,init-voltage-level =
				<RPMH_REGULATOR_LEVEL_RETENTION>;
		};
	};

	rpmh-regulator-ldof3 {
		compatible = "qcom,rpmh-vrm-regulator";
		qcom,resource-name = "ldof3";
		qcom,regulator-type = "pmic5-ldo";
		qcom,supported-modes =
			<RPMH_REGULATOR_MODE_LPM
			 RPMH_REGULATOR_MODE_HPM>;
		qcom,mode-threshold-currents = <0 30000>;
		proxy-supply = <&L3F>;

		L3F: pm_v8f_l3: vreg-pm_v8f-l3 {
			regulator-name = "pm_v8f_l3";
			qcom,set = <RPMH_REGULATOR_SET_ALL>;
			regulator-min-microvolt = <1200000>;
			regulator-max-microvolt = <1200000>;
			qcom,proxy-consumer-enable;
			qcom,proxy-consumer-current = <31000>;
			qcom,init-voltage = <1200000>;
			qcom,init-mode = <RPMH_REGULATOR_MODE_HPM>;
		};
	};

	rpmh-regulator-smpg2 {
		compatible = "qcom,rpmh-vrm-regulator";
		qcom,resource-name = "smpg2";

		S2G: pm_v6g_s2: vreg-pm_v6g-s2 {
			regulator-name = "pm_v6g_s2";
			qcom,set = <RPMH_REGULATOR_SET_ALL>;
			regulator-min-microvolt = <1010000>;
			regulator-max-microvolt = <1170000>;
			qcom,init-voltage = <1080000>;
		};
	};

	rpmh-regulator-ebilvl {
		compatible = "qcom,rpmh-arc-regulator";
		qcom,resource-name = "ebi.lvl";

		VDD_EBI_LEVEL:
		S3G_LEVEL:
		pm_v6g_s3_level: vreg-pm_v6g-s3-level {
			regulator-name = "pm_v6g_s3_level";
			qcom,set = <RPMH_REGULATOR_SET_ALL>;
			regulator-min-microvolt =
				<RPMH_REGULATOR_LEVEL_RETENTION>;
			regulator-max-microvolt = <RPMH_REGULATOR_LEVEL_MAX>;
			qcom,init-voltage-level =
				<RPMH_REGULATOR_LEVEL_RETENTION>;
		};
	};

	rpmh-regulator-smpg1 {
		compatible = "qcom,rpmh-vrm-regulator";
		qcom,resource-name = "smpg1";

		S1G: pm_v6g_s1: vreg-pm_v6g-s1 {
			regulator-name = "pm_v6g_s1";
			qcom,set = <RPMH_REGULATOR_SET_ALL>;
			regulator-min-microvolt = <2156000>;
			regulator-max-microvolt = <2400000>;
			qcom,init-voltage = <2200000>;
		};
	};

	rpmh-regulator-ldog1 {
		compatible = "qcom,rpmh-vrm-regulator";
		qcom,resource-name = "ldog1";
		qcom,regulator-type = "pmic5-ldo";
		qcom,supported-modes =
			<RPMH_REGULATOR_MODE_LPM
			 RPMH_REGULATOR_MODE_HPM>;
		qcom,mode-threshold-currents = <0 30000>;

		L1G: pm_v6g_l1: vreg-pm_v6g-l1 {
			regulator-name = "pm_v6g_l1";
			qcom,set = <RPMH_REGULATOR_SET_ALL>;
			regulator-min-microvolt = <1600000>;
			regulator-max-microvolt = <2000000>;
			qcom,init-voltage = <1800000>;
			qcom,init-mode = <RPMH_REGULATOR_MODE_HPM>;
		};
	};

	rpmh-regulator-ldog2 {
		compatible = "qcom,rpmh-vrm-regulator";
		qcom,resource-name = "ldog2";
		qcom,regulator-type = "pmic5-ldo";
		qcom,supported-modes =
			<RPMH_REGULATOR_MODE_RET
			 RPMH_REGULATOR_MODE_LPM
			 RPMH_REGULATOR_MODE_HPM>;
		qcom,mode-threshold-currents = <0 10000 30000>;

		L2G: pm_v6g_l2: vreg-pm_v6g-l2 {
			regulator-name = "pm_v6g_l2";
			qcom,set = <RPMH_REGULATOR_SET_ALL>;
			regulator-min-microvolt = <1200000>;
			regulator-max-microvolt = <1200000>;
			qcom,init-voltage = <1200000>;
			qcom,init-mode = <RPMH_REGULATOR_MODE_LPM>;
			regulator-always-on;
		};
	};

	rpmh-regulator-ldog3 {
		compatible = "qcom,rpmh-vrm-regulator";
		qcom,resource-name = "ldog3";
		qcom,regulator-type = "pmic5-ldo";
		qcom,supported-modes =
			<RPMH_REGULATOR_MODE_RET
			 RPMH_REGULATOR_MODE_LPM
			 RPMH_REGULATOR_MODE_HPM>;
		qcom,mode-threshold-currents = <0 10000 30000>;

		L3G: pm_v6g_l3: vreg-pm_v6g-l3 {
			regulator-name = "pm_v6g_l3";
			qcom,set = <RPMH_REGULATOR_SET_ALL>;
			regulator-min-microvolt = <1800000>;
			regulator-max-microvolt = <1800000>;
			qcom,init-voltage = <1800000>;
			qcom,init-mode = <RPMH_REGULATOR_MODE_LPM>;
		};
	};

	rpmh-regulator-smpi1 {
		compatible = "qcom,rpmh-vrm-regulator";
		qcom,resource-name = "smpi1";

		S1I: pmg1110i_s1: vreg-pmg1110i-s1 {
			regulator-name = "pmg1110i_s1";
			qcom,set = <RPMH_REGULATOR_SET_ALL>;
			regulator-min-microvolt = <352000>;
			regulator-max-microvolt = <952000>;
			qcom,init-voltage = <892000>;
		};
	};

	rpmh-regulator-smpj1 {
		compatible = "qcom,rpmh-vrm-regulator";
		qcom,resource-name = "smpj1";

		S1J: pmg1110j_s1: vreg-pmg1110j-s1 {
			regulator-name = "pmg1110j_s1";
			qcom,set = <RPMH_REGULATOR_SET_ALL>;
			regulator-min-microvolt = <504000>;
			regulator-max-microvolt = <868000>;
			qcom,init-voltage = <800000>;
		};
	};

	rpmh-regulator-ldok1 {
		compatible = "qcom,rpmh-vrm-regulator";
		qcom,resource-name = "ldok1";
		qcom,regulator-type = "pmic5-ldo";
		qcom,supported-modes =
			<RPMH_REGULATOR_MODE_LPM
			 RPMH_REGULATOR_MODE_HPM>;
		qcom,mode-threshold-currents = <0 30000>;

		L1K: pmr_nalojr_l1: vreg-pmr-nalojr-l1 {
			regulator-name = "pmr_nalojr_l1";
			qcom,set = <RPMH_REGULATOR_SET_ALL>;
			regulator-min-microvolt = <488000>;
			regulator-max-microvolt = <912000>;
			qcom,init-voltage = <850000>;
			qcom,init-mode = <RPMH_REGULATOR_MODE_HPM>;
		};
	};

	rpmh-regulator-ldok2 {
		compatible = "qcom,rpmh-vrm-regulator";
		qcom,resource-name = "ldok2";
		qcom,regulator-type = "pmic5-ldo";
		qcom,supported-modes =
			<RPMH_REGULATOR_MODE_LPM
			 RPMH_REGULATOR_MODE_HPM>;
		qcom,mode-threshold-currents = <0 30000>;

		L2K: pmr_nalojr_l2: vreg-pmr_nalojr_l2 {
			regulator-name = "pmr_nalojr_l2";
			qcom,set = <RPMH_REGULATOR_SET_ALL>;
			regulator-min-microvolt = <920000>;
			regulator-max-microvolt = <969000>;
			qcom,init-voltage = <952000>;
			qcom,init-mode = <RPMH_REGULATOR_MODE_HPM>;
		};
	};

	rpmh-regulator-ldok3 {
		compatible = "qcom,rpmh-vrm-regulator";
		qcom,resource-name = "ldok3";
		qcom,regulator-type = "pmic5-ldo";
		qcom,supported-modes =
			<RPMH_REGULATOR_MODE_LPM
			 RPMH_REGULATOR_MODE_HPM>;
		qcom,mode-threshold-currents = <0 30000>;

		L3K: pmr_nalojr_l3: vreg-pmr_nalojr_l3 {
			regulator-name = "pmr_nalojr_l3";
			qcom,set = <RPMH_REGULATOR_SET_ALL>;
			regulator-min-microvolt = <1080000>;
			regulator-max-microvolt = <1430000>;
			qcom,init-voltage = <1200000>;
			qcom,init-mode = <RPMH_REGULATOR_MODE_HPM>;
		};
	};

	rpmh-regulator-ldok4 {
		compatible = "qcom,rpmh-vrm-regulator";
		qcom,resource-name = "ldok4";
		qcom,regulator-type = "pmic5-ldo";
		qcom,supported-modes =
			<RPMH_REGULATOR_MODE_LPM
			 RPMH_REGULATOR_MODE_HPM>;
		qcom,mode-threshold-currents = <0 30000>;

		L4K: pmr_nalojr_l4: vreg-pmr_nalojr_l4 {
			regulator-name = "pmr_nalojr_l4";
			qcom,set = <RPMH_REGULATOR_SET_ALL>;
			regulator-min-microvolt = <1200000>;
			regulator-max-microvolt = <1200000>;
			qcom,init-voltage = <1200000>;
			qcom,init-mode = <RPMH_REGULATOR_MODE_HPM>;
		};
	};

	rpmh-regulator-ldok5 {
		compatible = "qcom,rpmh-vrm-regulator";
		qcom,resource-name = "ldok5";
		qcom,regulator-type = "pmic5-ldo";
		qcom,supported-modes =
			<RPMH_REGULATOR_MODE_LPM
			 RPMH_REGULATOR_MODE_HPM>;
		qcom,mode-threshold-currents = <0 30000>;

		L5K: pmr_nalojr_l5: vreg-pmr_nalojr_l5 {
			regulator-name = "pmr_nalojr_l5";
			qcom,set = <RPMH_REGULATOR_SET_ALL>;
			regulator-min-microvolt = <504000>;
			regulator-max-microvolt = <868000>;
			qcom,init-voltage = <800000>;
			qcom,init-mode = <RPMH_REGULATOR_MODE_HPM>;
		};
	};

	rpmh-regulator-ldok6 {
		compatible = "qcom,rpmh-vrm-regulator";
		qcom,resource-name = "ldok6";
		qcom,regulator-type = "pmic5-ldo";
		qcom,supported-modes =
			<RPMH_REGULATOR_MODE_LPM
			 RPMH_REGULATOR_MODE_HPM>;
		qcom,mode-threshold-currents = <0 30000>;

		L6K: pmr_nalojr_l6: vreg-pmr_nalojr_l6 {
			regulator-name = "pmr_nalojr_l6";
			qcom,set = <RPMH_REGULATOR_SET_ALL>;
			regulator-min-microvolt = <1100000>;
			regulator-max-microvolt = <2000000>;
			qcom,init-voltage = <1776000>;
			qcom,init-mode = <RPMH_REGULATOR_MODE_LPM>;
		};
	};

	rpmh-regulator-ldok7 {
		compatible = "qcom,rpmh-vrm-regulator";
		qcom,resource-name = "ldok7";
		qcom,regulator-type = "pmic5-ldo";
		qcom,supported-modes =
			<RPMH_REGULATOR_MODE_LPM
			 RPMH_REGULATOR_MODE_HPM>;
		qcom,mode-threshold-currents = <0 30000>;

		L7K: pmr_nalojr_l7: vreg-pmr_nalojr_l7 {
			regulator-name = "pmr_nalojr_l7";
			qcom,set = <RPMH_REGULATOR_SET_ALL>;
			regulator-min-microvolt = <504000>;
			regulator-max-microvolt = <868000>;
			qcom,init-voltage = <800000>;
			qcom,init-mode = <RPMH_REGULATOR_MODE_HPM>;
		};
	};

	rpmh-regulator-ldom1 {
		compatible = "qcom,rpmh-vrm-regulator";
		qcom,resource-name = "ldom1";
		qcom,regulator-type = "pmic5-ldo";
		qcom,supported-modes =
			<RPMH_REGULATOR_MODE_LPM
			 RPMH_REGULATOR_MODE_HPM>;
		qcom,mode-threshold-currents = <0 30000>;

		L1M: pm8010m_l1: vreg-pm8010m-l1 {
			regulator-name = "pm8010m_l1";
			qcom,set = <RPMH_REGULATOR_SET_ALL>;
			regulator-min-microvolt = <1000000>;
			regulator-max-microvolt = <1200000>;
			qcom,init-voltage = <1104000>;
			qcom,init-mode = <RPMH_REGULATOR_MODE_HPM>;
		};
	};

	rpmh-regulator-ldom2 {
		compatible = "qcom,rpmh-vrm-regulator";
		qcom,resource-name = "ldom2";
		qcom,regulator-type = "pmic5-ldo";
		qcom,supported-modes =
			<RPMH_REGULATOR_MODE_LPM
			 RPMH_REGULATOR_MODE_HPM>;
		qcom,mode-threshold-currents = <0 30000>;

		L2M: pm8010m_l2: vreg-pm8010m-l2 {
			regulator-name = "pm8010m_l2";
			qcom,set = <RPMH_REGULATOR_SET_ALL>;
			regulator-min-microvolt = <950000>;
			regulator-max-microvolt = <1150000>;
			qcom,init-voltage = <1056000>;
			qcom,init-mode = <RPMH_REGULATOR_MODE_HPM>;
		};
	};

	rpmh-regulator-ldom3 {
		compatible = "qcom,rpmh-vrm-regulator";
		qcom,resource-name = "ldom3";

		L3M:
		pm8010m_l3: vreg-pm8010m-l3 {
			regulator-name = "pm8010m_l3";
			qcom,set = <RPMH_REGULATOR_SET_ALL>;
			regulator-min-microvolt = <2700000>;
			regulator-max-microvolt = <2900000>;
			qcom,init-voltage = <2800000>;
		};
	};

	rpmh-regulator-ldom4 {
		compatible = "qcom,rpmh-vrm-regulator";
		qcom,resource-name = "ldom4";

		L4M:
		pm8010m_l4: vreg-pm8010m-l4 {
			regulator-name = "pm8010m_l4";
			qcom,set = <RPMH_REGULATOR_SET_ALL>;
			regulator-min-microvolt = <2700000>;
			regulator-max-microvolt = <2900000>;
			qcom,init-voltage = <2800000>;
		};
	};

	rpmh-regulator-ldom5 {
		compatible = "qcom,rpmh-vrm-regulator";
		qcom,resource-name = "ldom5";
		status = "disabled";

		L5M:
		pm8010m_l5: vreg-pm8010m-l5 {
			regulator-name = "pm8010m_l5";
			qcom,set = <RPMH_REGULATOR_SET_ALL>;
			regulator-min-microvolt = <1200000>;
			regulator-max-microvolt = <1200000>;
			qcom,init-voltage = <1200000>;
			status = "disabled";
		};
	};

	rpmh-regulator-ldom6 {
		compatible = "qcom,rpmh-vrm-regulator";
		qcom,resource-name = "ldom6";

		L6M:
		pm8010m_l6: vreg-pm8010m-l6 {
			regulator-name = "pm8010m_l6";
			qcom,set = <RPMH_REGULATOR_SET_ALL>;
			regulator-min-microvolt = <2700000>;
			regulator-max-microvolt = <2900000>;
			qcom,init-voltage = <2800000>;
		};
	};

	rpmh-regulator-ldom7 {
		compatible = "qcom,rpmh-vrm-regulator";
		qcom,resource-name = "ldom7";

		L7M:
		pm8010m_l7: vreg-pm8010m-l7 {
			regulator-name = "pm8010m_l7";
			qcom,set = <RPMH_REGULATOR_SET_ALL>;
			regulator-min-microvolt = <2700000>;
			regulator-max-microvolt = <3000000>;
			qcom,init-voltage = <2800000>;
		};
	};

	rpmh-regulator-ldon1 {
		compatible = "qcom,rpmh-vrm-regulator";
		qcom,resource-name = "ldon1";
		qcom,regulator-type = "pmic5-ldo";
		qcom,supported-modes =
			<RPMH_REGULATOR_MODE_LPM
			 RPMH_REGULATOR_MODE_HPM>;
		qcom,mode-threshold-currents = <0 30000>;

		L1N: pm8010n_l1: vreg-pm8010n-l1 {
			regulator-name = "pm8010n_l1";
			qcom,set = <RPMH_REGULATOR_SET_ALL>;
			regulator-min-microvolt = <1050000>;
			regulator-max-microvolt = <1200000>;
			qcom,init-voltage = <1104000>;
			qcom,init-mode = <RPMH_REGULATOR_MODE_HPM>;
		};
	};

	rpmh-regulator-ldon2 {
		compatible = "qcom,rpmh-vrm-regulator";
		qcom,resource-name = "ldon2";
		qcom,regulator-type = "pmic5-ldo";
		qcom,supported-modes =
			<RPMH_REGULATOR_MODE_LPM
			 RPMH_REGULATOR_MODE_HPM>;
		qcom,mode-threshold-currents = <0 30000>;

		L2N: pm8010n_l2: vreg-pm8010n-l2 {
			regulator-name = "pm8010n_l2";
			qcom,set = <RPMH_REGULATOR_SET_ALL>;
			regulator-min-microvolt = <1050000>;
			regulator-max-microvolt = <1150000>;
			qcom,init-voltage = <1104000>;
			qcom,init-mode = <RPMH_REGULATOR_MODE_HPM>;
		};
	};

	rpmh-regulator-ldon3 {
		compatible = "qcom,rpmh-vrm-regulator";
		qcom,resource-name = "ldon3";

		L3N: pm8010n_l3: vreg-pm8010n-l3 {
			regulator-name = "pm8010n_l3";
			qcom,set = <RPMH_REGULATOR_SET_ALL>;
			regulator-min-microvolt = <1792000>;
			regulator-max-microvolt = <1900000>;
			qcom,init-voltage = <1800000>;
		};
	};

	rpmh-regulator-ldon4 {
		compatible = "qcom,rpmh-vrm-regulator";
		qcom,resource-name = "ldon4";
		status = "disabled";

		L4N: pm8010n_l4: vreg-pm8010n-l4 {
			regulator-name = "pm8010n_l4";
			qcom,set = <RPMH_REGULATOR_SET_ALL>;
			regulator-min-microvolt = <1792000>;
			regulator-max-microvolt = <3312000>;
			qcom,init-voltage = <1800000>;
			status = "disabled";
		};
	};

	rpmh-regulator-ldon5 {
		compatible = "qcom,rpmh-vrm-regulator";
		qcom,resource-name = "ldon5";

		L5N: pm8010n_l5: vreg-pm8010n-l5 {
			regulator-name = "pm8010n_l5";
			qcom,set = <RPMH_REGULATOR_SET_ALL>;
			regulator-min-microvolt = <1504000>;
			regulator-max-microvolt = <1980000>;
			qcom,init-voltage = <1800000>;
		};
	};

	rpmh-regulator-ldon6 {
		compatible = "qcom,rpmh-vrm-regulator";
		qcom,resource-name = "ldon6";

		L6N: pm8010n_l6: vreg-pm8010n-l6 {
			regulator-name = "pm8010n_l6";
			qcom,set = <RPMH_REGULATOR_SET_ALL>;
			regulator-min-microvolt = <2700000>;
			regulator-max-microvolt = <2900000>;
			qcom,init-voltage = <2800000>;
		};
	};

	rpmh-regulator-ldon7 {
		compatible = "qcom,rpmh-vrm-regulator";
		qcom,resource-name = "ldon7";

		L7N: pm8010n_l7: vreg-pm8010n-l7 {
			regulator-name = "pm8010n_l7";
			qcom,set = <RPMH_REGULATOR_SET_ALL>;
			regulator-min-microvolt = <3130000>;
			regulator-max-microvolt = <3470000>;
			qcom,init-voltage = <3304000>;
		};
	};

	rpmh-regulator-vrm-wcal {
		compatible = "qcom,rpmh-pbs-regulator";
		qcom,resource-name = "vrm.wcal";

		WCAL_PBS:
		pmk8550_wcal_pbs: regulator-pmk8550-wcal-pbs {
			regulator-name = "pmk8550_wcal_pbs";
			qcom,set = <RPMH_REGULATOR_SET_ALL>;
		};
	};
};
